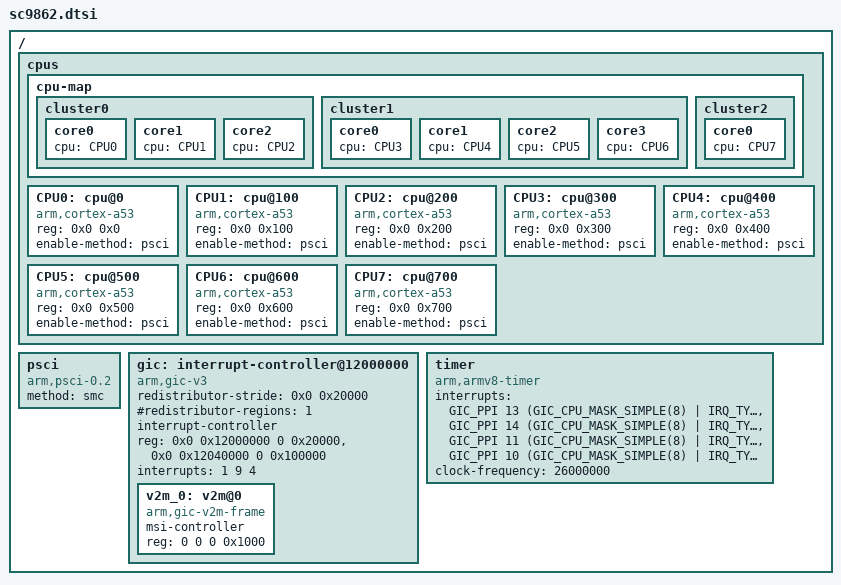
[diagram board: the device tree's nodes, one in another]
/*
 * Spreadtrum SP9862 SoC DTS file
 *
 * Copyright (C) 2016, Spreadtrum Communications Inc.
 *
 * This file is licensed under a dual GPLv2 or X11 license.
 */

#include "whalek.dtsi"

/ {
	cpus {
		#address-cells = <2>;
		#size-cells = <0>;

		cpu-map {
			cluster0 {
				core0 {
					cpu = <&CPU0>;
				};
				core1 {
					cpu = <&CPU1>;
				};
				core2 {
					cpu = <&CPU2>;
				};
			};
			cluster1 {
				core0 {
					cpu = <&CPU3>;
				};
				core1 {
					cpu = <&CPU4>;
				};
				core2 {
					cpu = <&CPU5>;
				};
				core3 {
					cpu = <&CPU6>;
				};
			};
			cluster2 {
				core0 {
					cpu = <&CPU7>;
				};
			};
		};

		CPU0: cpu@0 {
			device_type = "cpu";
			compatible = "arm,cortex-a53","arm,armv8";
			reg = <0x0 0x0>;
			enable-method = "psci";
		};
		CPU1: cpu@100 {
			device_type = "cpu";
			compatible = "arm,cortex-a53","arm,armv8";
			reg = <0x0 0x100>;
			enable-method = "psci";
		};
		CPU2: cpu@200 {
			device_type = "cpu";
			compatible = "arm,cortex-a53","arm,armv8";
			reg = <0x0 0x200>;
			enable-method = "psci";
		};
		CPU3: cpu@300 {
			device_type = "cpu";
			compatible = "arm,cortex-a53","arm,armv8";
			reg = <0x0 0x300>;
			enable-method = "psci";
		};
		CPU4: cpu@400 {
			device_type = "cpu";
			compatible = "arm,cortex-a53","arm,armv8";
			reg = <0x0 0x400>;
			enable-method = "psci";
		};

		CPU5: cpu@500 {
			device_type = "cpu";
			compatible = "arm,cortex-a53","arm,armv8";
			reg = <0x0 0x500>;
			enable-method = "psci";
		};
		CPU6: cpu@600 {
			device_type = "cpu";
			compatible = "arm,cortex-a53","arm,armv8";
			reg = <0x0 0x600>;
			enable-method = "psci";
		};
		CPU7: cpu@700 {
			device_type = "cpu";
			compatible = "arm,cortex-a53","arm,armv8";
			reg = <0x0 0x700>;
			enable-method = "psci";
		};
	};

	psci {
		compatible = "arm,psci-0.2";
		method = "smc";
	};

	gic: interrupt-controller@12000000 {
		compatible = "arm,gic-v3";
		#interrupt-cells = <3>;
		#address-cells = <2>;
		#size-cells = <2>;
		ranges;
		redistributor-stride = <0x0 0x20000>;	// 128KB stride
		#redistributor-regions = <1>;
		interrupt-controller;
		reg = <0x0 0x12000000 0 0x20000>,	// GICD
			<0x0 0x12040000 0 0x100000>;	// GICR
		interrupts = <1 9 4>;
		v2m_0: v2m@0 {
			compatible = "arm,gic-v2m-frame";
			msi-controller;
			reg = <0 0 0 0x1000>;
		};
	};

	timer {
		compatible = "arm,armv8-timer";
		interrupts = <GIC_PPI 13 (GIC_CPU_MASK_SIMPLE(8)
					 | IRQ_TYPE_LEVEL_LOW)>,
			     <GIC_PPI 14 (GIC_CPU_MASK_SIMPLE(8)
					 | IRQ_TYPE_LEVEL_LOW)>,
			     <GIC_PPI 11 (GIC_CPU_MASK_SIMPLE(8)
					 | IRQ_TYPE_LEVEL_LOW)>,
			     <GIC_PPI 10 (GIC_CPU_MASK_SIMPLE(8)
					 | IRQ_TYPE_LEVEL_LOW)>;
		clock-frequency = <26000000>;
	};
};
